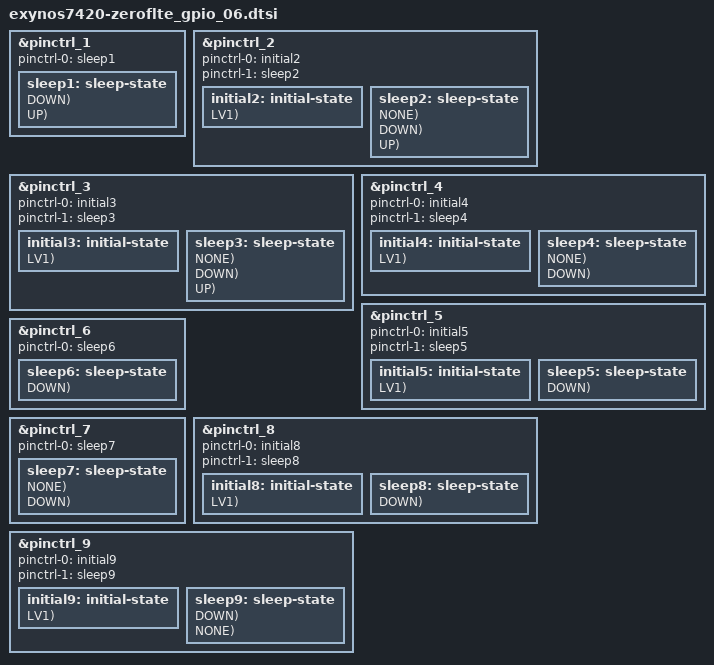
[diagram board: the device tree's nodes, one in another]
/*
 * Copyright (c) 2014 Samsung Electronics Co., Ltd.
 *		http://www.samsung.com
 *
 * This program is free software; you can redistribute it and/or modify
 * it under the terms of the GNU General Public License version 2 as
 * published by the Free Software Foundation.
*/

// Support ZERO-F LTE HW REV06 (b1010)

#include "exynos_gpio_config_macros.dtsi"

// gpz0, gpz1
&pinctrl_1 {
	pinctrl-names = "sleep";
	pinctrl-0 = <&sleep1>;
	sleep1: sleep-state {
		PIN_SLP(gpz0-0, INPUT, DOWN);	/* MM_I2S_CLK */
		PIN_SLP(gpz0-1, INPUT, DOWN);	/* NC */
		PIN_SLP(gpz0-2, INPUT, DOWN);	/* MM_I2S_SYNC */
		PIN_SLP(gpz0-3, INPUT, DOWN);	/* MM_I2S_DO */
		PIN_SLP(gpz0-4, INPUT, DOWN);	/* MM_I2S_DI */
		PIN_SLP(gpz0-5, INPUT, DOWN);	/* NC */
		PIN_SLP(gpz0-6, INPUT, DOWN);	/* NC */

		PIN_SLP(gpz1-0, OUT1, UP);	/* BT_UART_TXD */
		PIN_SLP(gpz1-1, INPUT, UP);	/* BT_UART_RXD */
		PIN_SLP(gpz1-2, INPUT, UP);	/* BT_UART_CTS */
		PIN_SLP(gpz1-3, OUT1, UP);	/* BT_UART_RTS */
	};
};

// gpb0, gpc0 ~ gpc3, gpd0 ~ gpd8, gpg0, gpg3
&pinctrl_2 {
	pinctrl-names = "default","sleep";
	pinctrl-0 = <&initial2>;
	pinctrl-1 = <&sleep2>;
	initial2: initial-state {
		PIN_IN(gpd0-0, DOWN, LV1);	/* NC */
		PIN_IN(gpd0-1, DOWN, LV1);	/* NC */

		PIN_IN(gpd1-4, DOWN, LV1);	/* NC */
		PIN_IN(gpd1-5, DOWN, LV1);	/* NC */

		PIN_IN(gpd2-4, DOWN, LV1);	/* NC */
		PIN_IN(gpd2-6, DOWN, LV1);	/* NC */
		PIN_IN(gpd2-7, DOWN, LV1);	/* NC */

		PIN_IN(gpd4-0, DOWN, LV1);	/* NC */
		PIN_IN(gpd4-1, DOWN, LV1);	/* NC */
		PIN_IN(gpd4-2, DOWN, LV1);	/* NC */
		PIN_IN(gpd4-3, DOWN, LV1);	/* NC */
		PIN_IN(gpd4-4, DOWN, LV1);	/* NC */
	};
	sleep2: sleep-state {
		PIN_SLP(gpb0-0, INPUT, NONE);	/* MEM_SDA */
		PIN_SLP(gpb0-1, INPUT, NONE);	/* MEM_SCL */
		PIN_SLP(gpb0-2, INPUT, DOWN);	/* VTCAM_EEP_SDA */
		PIN_SLP(gpb0-3, INPUT, DOWN);	/* VTCAM_EEP_SCL */
		PIN_SLP(gpb0-4, OUT0, NONE);	/* BUCK6EN */

		PIN_SLP(gpc0-0, INPUT, DOWN);	/* COMP_PAF_INT */
		PIN_SLP(gpc0-1, INPUT, DOWN);	/* TP */
		PIN_SLP(gpc0-2, INPUT, DOWN);	/* CAM_FLASH_EN */
		PIN_SLP(gpc0-3, INPUT, DOWN);	/* CAM_TORCH_EN */
		PIN_SLP(gpc0-4, INPUT, DOWN);	/* VTCAM_RST_N */
		PIN_SLP(gpc0-5, INPUT, DOWN);	/* CAM_RST_N */
		PIN_SLP(gpc0-6, INPUT, DOWN);	/* VTCAM_STBY */
		PIN_SLP(gpc0-7, INPUT, DOWN);	/* COMP_RST_N */

		PIN_SLP(gpc1-0, INPUT, DOWN);	/* CAM_SENSOR_DET */
		PIN_SLP(gpc1-1, INPUT, DOWN);	/* TP */

		PIN_SLP(gpc2-0, INPUT, DOWN);	/* CAM_SDA */
		PIN_SLP(gpc2-1, INPUT, DOWN);	/* CAM_SCL */
		PIN_SLP(gpc2-2, INPUT, DOWN);	/* VTCAM_SDA */
		PIN_SLP(gpc2-3, INPUT, DOWN);	/* VTCAM_SCL */
		PIN_SLP(gpc2-4, INPUT, DOWN);	/* OIS_AF_SDA */
		PIN_SLP(gpc2-5, INPUT, DOWN);	/* OIS_AF_SCL */

		PIN_SLP(gpc3-0, INPUT, DOWN);	/* FROM_SPI_SCLK */
		PIN_SLP(gpc3-1, INPUT, DOWN);	/* FROM_SPI_SSN */
		PIN_SLP(gpc3-2, INPUT, DOWN);	/* FROM_SPI_MISO */
		PIN_SLP(gpc3-3, INPUT, DOWN);	/* FROM_SPI_MOSI */
		PIN_SLP(gpc3-4, INPUT, DOWN);	/* COMP_SPI_SCLK */
		PIN_SLP(gpc3-5, INPUT, DOWN);	/* COMP_SPI_SSN */
		PIN_SLP(gpc3-6, INPUT, DOWN);	/* COMP_SPI_MISO */
		PIN_SLP(gpc3-7, INPUT, DOWN);	/* COMP_SPI_MOSI */

		PIN_SLP(gpd0-0, INPUT, DOWN);	/* NC */
		PIN_SLP(gpd0-1, INPUT, DOWN);	/* NC */
		PIN_SLP(gpd0-2, INPUT, NONE);	/* SUB_PMIC_SDA */
		PIN_SLP(gpd0-3, INPUT, NONE);	/* SUB_PMIC_SCL */

		PIN_SLP(gpd1-0, INPUT, DOWN);	/* AP_RXD */
		PIN_SLP(gpd1-1, INPUT, DOWN);	/* AP_TXD */
		PIN_SLP(gpd1-2, INPUT, DOWN);	/* TOUCH_SDA */
		PIN_SLP(gpd1-3, INPUT, DOWN);	/* TOUCH_SCL */
		PIN_SLP(gpd1-4, INPUT, DOWN);	/* NC */
		PIN_SLP(gpd1-5, INPUT, DOWN);	/* NC */

		PIN_SLP(gpd2-0, INPUT, NONE);	/* SPK_AMP_SDA */
		PIN_SLP(gpd2-1, INPUT, NONE);	/* SPK_AMP_SCL */
		PIN_SLP(gpd2-2, INPUT, NONE);	/* IF_PMIC_SDA */
		PIN_SLP(gpd2-3, INPUT, NONE);	/* IF_PMIC_SCL */
		PIN_SLP(gpd2-4, INPUT, DOWN);	/* NC */
		PIN_SLP(gpd2-5, OUT0, NONE);	/* VIBTONE_PWM */
		PIN_SLP(gpd2-6, INPUT, DOWN);	/* NC */
		PIN_SLP(gpd2-7, INPUT, DOWN);	/* NC */

		PIN_SLP(gpd4-0, INPUT, DOWN);	/* NC */
		PIN_SLP(gpd4-1, INPUT, DOWN);	/* NC  */
		PIN_SLP(gpd4-2, INPUT, DOWN);	/* NC */
		PIN_SLP(gpd4-3, INPUT, DOWN);	/* NC */
		PIN_SLP(gpd4-4, INPUT, DOWN);	/* NC */

		PIN_SLP(gpd5-0, INPUT, DOWN);	/* CP_SPI_CLK */
		PIN_SLP(gpd5-1, INPUT, DOWN);	/* CP_SPI_CSN */
		PIN_SLP(gpd5-2, INPUT, DOWN);	/* CP_SPI_MISO */
		PIN_SLP(gpd5-3, INPUT, DOWN);	/* CP_SPI_MOSI */

		PIN_SLP(gpd6-0, INPUT, DOWN);	/* CODEC_SPI_MOSI */
		PIN_SLP(gpd6-1, INPUT, DOWN);	/* CODEC_SPI_MISO */
		PIN_SLP(gpd6-2, OUT1, UP);	/* SHUB_SPI_SCK */
		PIN_SLP(gpd6-3, OUT1, UP);	/* SHUB_SPI_CSN */
		PIN_SLP(gpd6-4, INPUT, DOWN);	/* SHUB_SPI_MISO */
		PIN_SLP(gpd6-5, OUT1, UP);	/* SHUB_SPI_MOSI */

		PIN_SLP(gpd7-0, INPUT, DOWN);	/* CAM_MCLK */
		PIN_SLP(gpd7-1, INPUT, DOWN);	/* COMP_MCLK */
		PIN_SLP(gpd7-2, INPUT, DOWN);	/* VTCAM_MCLK */

		PIN_SLP(gpd8-0, INPUT, DOWN);	/* CODEC_SPI_SCK */
		PIN_SLP(gpd8-1, INPUT, DOWN);	/* CODEC_SPI_SSN */

		PIN_SLP(gpg0-0, INPUT, DOWN);	/* DISPLAY_TE */
		PIN_SLP(gpg0-1, INPUT, DOWN);	/* DISPLAY_TE */

		PIN_SLP(gpg3-0, INPUT, NONE);	/* AP_PMIC_SDA */
		PIN_SLP(gpg3-1, INPUT, NONE);	/* AP_PMIC_SCL */
		PIN_SLP(gpg3-2, INPUT, NONE);	/* WPC_SDA */
		PIN_SLP(gpg3-3, INPUT, NONE);	/* WPC_SCL */
	};
};

// gpf0 ~ gpf5, gpg1, gpg2, gph1, gpv6
&pinctrl_3 {
	pinctrl-names = "default","sleep";
	pinctrl-0 = <&initial3>;
	pinctrl-1 = <&sleep3>;
	initial3: initial-state {
		PIN_IN(gpf0-0, NONE, LV1);	/* HW_REV(0) */
		PIN_IN(gpf0-1, NONE, LV1);	/* HW_REV(1) */
		PIN_IN(gpf0-2, NONE, LV1);	/* HW_REV(2) */
		PIN_IN(gpf0-3, NONE, LV1);	/* HW_REV(3) */
		PIN_IN(gpf0-5, DOWN, LV1);	/* NC */

		PIN_IN(gpf1-0, DOWN, LV1);	/* NC */
		PIN_IN(gpf1-2, DOWN, LV1);	/* NC */
		PIN_IN(gpf1-3, DOWN, LV1);	/* NC */

		PIN_IN(gpf2-0, DOWN, LV1);	/* NC */
		PIN_IN(gpf2-1, DOWN, LV1);	/* NC */
		PIN_IN(gpf2-2, DOWN, LV1);	/* NC */
		PIN_IN(gpf2-3, DOWN, LV1);	/* NC */

		PIN_IN(gpf3-1, DOWN, LV1);	/* FPS_ID */
		PIN_IN(gpf3-2, DOWN, LV1);	/* NC */

		PIN_IN(gpf5-3, DOWN, LV1);	/* NC */
		PIN_IN(gpf5-5, DOWN, LV1);	/* NC */
		PIN_IN(gpf5-6, DOWN, LV1);	/* WCP_TSB */
		PIN_IN(gpf5-7, DOWN, LV1);	/* NC */

		PIN_IN(gpg1-2, DOWN, LV1);	/* NC */
		PIN_IN(gpg1-3, DOWN, LV1);	/* NC */

		PIN_IN(gph1-0, DOWN, LV1);	/* NC */
		PIN_IN(gph1-1, DOWN, LV1);	/* NC */
		PIN_IN(gph1-2, DOWN, LV1);	/* NC */
		PIN_IN(gph1-3, DOWN, LV1);	/* NC */

		PIN_IN(gpv6-0, DOWN, LV1);	/* NC */
		PIN_IN(gpv6-1, DOWN, LV1);	/* NC */
		PIN_IN(gpv6-2, DOWN, LV1);	/* NC */
	};
	sleep3: sleep-state {
		PIN_SLP(gpf0-0, INPUT, NONE);	/* HW_REV(0) */
		PIN_SLP(gpf0-1, INPUT, NONE);	/* HW_REV(1) */
		PIN_SLP(gpf0-2, INPUT, NONE);	/* HW_REV(2) */
		PIN_SLP(gpf0-3, INPUT, NONE);	/* HW_REV(3) */
		PIN_SLP(gpf0-4, PREV, NONE);	/* AP_CP_STATUS */
		PIN_SLP(gpf0-5, INPUT, DOWN);	/* NC */
		PIN_SLP(gpf0-6, PREV, NONE);	/* PCIE_CLKREQ_L */
		PIN_SLP(gpf0-7, PREV, DOWN);	/* XCCIBYPASS */

		PIN_SLP(gpf1-0, INPUT, DOWN);	/* NC */
		PIN_SLP(gpf1-1, PREV, NONE);	/* CP_RST_N */
		PIN_SLP(gpf1-2, INPUT, DOWN);	/* NC */
		PIN_SLP(gpf1-3, INPUT, DOWN);	/* NC */
		PIN_SLP(gpf1-4, INPUT, DOWN);	/* VTCAM_ID */
		PIN_SLP(gpf1-5, PREV, NONE);	/* NFC_EN */
		PIN_SLP(gpf1-6, PREV, NONE);	/* BTP_LDO_EN1 */
		PIN_SLP(gpf1-7, PREV, NONE);	/* BTP_LDO_EN2 */

		PIN_SLP(gpf2-0, INPUT, DOWN);	/* NC */
		PIN_SLP(gpf2-1, INPUT, DOWN);	/* NC */
		PIN_SLP(gpf2-2, INPUT, DOWN);	/* NC */
		PIN_SLP(gpf2-3, INPUT, DOWN);	/* NC */

		PIN_SLP(gpf3-0, OUT1, NONE);	/* PMIC_WRST_IN */
		PIN_SLP(gpf3-1, INPUT, DOWN);	/* FPS_ID */
		PIN_SLP(gpf3-2, INPUT, DOWN);	/* NC */
		PIN_SLP(gpf3-3, OUT0, NONE);	/* PDA_ACTIVE */
		PIN_SLP(gpf3-4, PREV, NONE);	/* BTP_RST_N */

		PIN_SLP(gpf4-0, PREV, NONE);	/* CODEC_RST_N */
		PIN_SLP(gpf4-1, PREV, NONE);	/* BT_EN */
		PIN_SLP(gpf4-2, PREV, NONE);	/* AP_CP_WAKE */
		PIN_SLP(gpf4-3, OUT0, NONE);	/* DISPLAY_1.6V_EN */
		PIN_SLP(gpf4-4, INPUT, DOWN);	/* SSP_MCU_RESP */
		PIN_SLP(gpf4-5, OUT0, DOWN);	/* SSP_MCU_REQ */
		PIN_SLP(gpf4-6, PREV, NONE);	/* WLAN_EN */
		PIN_SLP(gpf4-7, PREV, NONE);	/* GPS_HUB_EN */

		PIN_SLP(gpf5-0, PREV, NONE);	/* CP_PMIC_PWR_EN */
		PIN_SLP(gpf5-1, PREV, NONE);	/* AP_CP_DUMP_NOTI_n */
		PIN_SLP(gpf5-2, PREV, NONE);	/* FACTORY_DISCHARGING */
		PIN_SLP(gpf5-3, INPUT, DOWN);	/* NC */
		PIN_SLP(gpf5-4, OUT0, DOWN);	/* NFC_FIRM */
		PIN_SLP(gpf5-5, INPUT, DOWN);	/* NC */
		PIN_SLP(gpf5-6, INPUT, DOWN);	/* WCP_TSB */
		PIN_SLP(gpf5-7, INPUT, DOWN);	/* NC */

		PIN_SLP(gpg1-0, INPUT, NONE);	/* SMPL_WARN_AP */
		PIN_SLP(gpg1-1, PREV, NONE);	/* PMIC_BUCK6_DVS */
		PIN_SLP(gpg1-2, INPUT, DOWN);	/* NC */
		PIN_SLP(gpg1-3, INPUT, DOWN);	/* NC */
		PIN_SLP(gpg1-4, INPUT, DOWN);	/* TSP_ID */

		PIN_SLP(gpg2-0, PREV, NONE);	/* PCIE_RST_L */
		PIN_SLP(gpg2-1, INPUT, DOWN);	/* PAD_DBGSRCSEL */
		PIN_SLP(gpg2-2, PREV, UP);	/* PCIE_LINK_RESET */
		PIN_SLP(gpg2-3, PREV, DOWN);	/* XCPUAXI3SELACE */
		PIN_SLP(gpg2-4, PREV, NONE);	/* UFS_REFCLK */

		PIN_SLP(gph1-0, INPUT, DOWN);	/* NC */
		PIN_SLP(gph1-1, INPUT, DOWN);	/* NC */
		PIN_SLP(gph1-2, INPUT, DOWN);	/* NC */
		PIN_SLP(gph1-3, INPUT, DOWN);	/* NC */
		PIN_SLP(gph1-4, OUT0, NONE);	/* XBOOTLDO0 */
		PIN_SLP(gph1-5, PREV, NONE);	/* UFS_RST_N */

		PIN_SLP(gpv6-0, INPUT, DOWN);	/* NC */
		PIN_SLP(gpv6-1, INPUT, DOWN);	/* NC */
		PIN_SLP(gpv6-2, INPUT, DOWN);	/* NC */
	};
};

// gpj0
&pinctrl_4 {
	pinctrl-names = "default","sleep";
	pinctrl-0 = <&initial4>;
	pinctrl-1 = <&sleep4>;
	initial4: initial-state {
		PIN_IN(gpj0-2, DOWN, LV1);	/* NC */
	};
	sleep4: sleep-state {
		PIN_SLP(gpj0-0, INPUT, NONE);	/* HRM_SDA */
		PIN_SLP(gpj0-1, INPUT, NONE);	/* HRM_SCL */
		PIN_SLP(gpj0-2, INPUT, DOWN);	/* NC */
	};
};

// gpj1
&pinctrl_5 {
	pinctrl-names = "default","sleep";
	pinctrl-0 = <&initial5>;
	pinctrl-1 = <&sleep5>;
	initial5: initial-state {
		PIN_IN(gpj1-2, DOWN, LV1);	/* NC */
	};
	sleep5: sleep-state {
		PIN_SLP(gpj1-0, INPUT, DOWN);	/* TSP_SDA */
		PIN_SLP(gpj1-1, INPUT, DOWN);	/* TSP_SCL */
		PIN_SLP(gpj1-2, INPUT, DOWN);	/* NC */
	};
};

// gpg4
&pinctrl_6 {
	pinctrl-names = "sleep";
	pinctrl-0 = <&sleep6>;
	sleep6: sleep-state {
		PIN_SLP(gpg4-0, INPUT, DOWN);	/* ESE_SPI_SCLK */
		PIN_SLP(gpg4-1, INPUT, DOWN);	/* ESE_SPI_SSN */
		PIN_SLP(gpg4-2, INPUT, DOWN);	/* ESE_SPI_MISO */
		PIN_SLP(gpg4-3, INPUT, DOWN);	/* ESE_SPI_MOSI */
	};
};

// gpv7
&pinctrl_7 {
	pinctrl-names = "sleep";
	pinctrl-0= <&sleep7>;
	sleep7: sleep-state {
		PIN_SLP(gpv7-0, OUT0, NONE);	/* BTP_SPI_CLK */
		PIN_SLP(gpv7-1, OUT0, NONE);	/* BTP_SPI_CS_N */
		PIN_SLP(gpv7-2, INPUT, DOWN);	/* BTP_SPI_MISO */
		PIN_SLP(gpv7-3, OUT0, NONE);	/* BTP_SPI_MOSI */
		PIN_SLP(gpv7-4, PREV, NONE);	/* BTP_OCP_EN */
	};
};

// gpr4
&pinctrl_8 {
	pinctrl-names = "default","sleep";
	pinctrl-0 = <&initial8>;
	pinctrl-1 = <&sleep8>;
	initial8: initial-state {
		PIN_IN(gpr4-0, DOWN, LV1);	/* NC */
		PIN_IN(gpr4-1, DOWN, LV1);	/* NC */
		PIN_IN(gpr4-2, DOWN, LV1);	/* NC */
		PIN_IN(gpr4-3, DOWN, LV1);	/* NC */
		PIN_IN(gpr4-4, DOWN, LV1);	/* NC */
		PIN_IN(gpr4-5, DOWN, LV1);	/* NC */
		PIN_IN(gpr4-6, DOWN, LV1);	/* NC */
	};
	sleep8: sleep-state {
		PIN_SLP(gpr4-0, INPUT, DOWN);	/* NC */
		PIN_SLP(gpr4-1, INPUT, DOWN);	/* NC */
		PIN_SLP(gpr4-2, INPUT, DOWN);	/* NC */
		PIN_SLP(gpr4-3, INPUT, DOWN);	/* NC */
		PIN_SLP(gpr4-4, INPUT, DOWN);	/* NC */
		PIN_SLP(gpr4-5, INPUT, DOWN);	/* NC */
		PIN_SLP(gpr4-6, INPUT, DOWN);	/* NC */
	};
};

// gpr0 ~ gpr3
&pinctrl_9 {
	pinctrl-names = "default","sleep";
	pinctrl-0 = <&initial9>;
	pinctrl-1 = <&sleep9>;
	initial9: initial-state {
		PIN_IN(gpr0-0, DOWN, LV1);	/* NC */
		PIN_IN(gpr0-1, DOWN, LV1);	/* NC */
		PIN_IN(gpr0-2, DOWN, LV1);	/* NC */
		PIN_IN(gpr0-3, DOWN, LV1);	/* NC */

		PIN_IN(gpr1-0, DOWN, LV1);	/* NC */
		PIN_IN(gpr1-1, DOWN, LV1);	/* NC */
		PIN_IN(gpr1-2, DOWN, LV1);	/* NC */
		PIN_IN(gpr1-3, DOWN, LV1);	/* NC */
		PIN_IN(gpr1-4, DOWN, LV1);	/* NC */
		PIN_IN(gpr1-5, DOWN, LV1);	/* NC */
		PIN_IN(gpr1-6, DOWN, LV1);	/* NC */
		PIN_IN(gpr1-7, DOWN, LV1);	/* NC */

		PIN_IN(gpr2-3, DOWN, LV1);	/* NC */
		PIN_IN(gpr2-4, DOWN, LV1);	/* NC */

		PIN_IN(gpr3-2, DOWN, LV1);	/* NC */
	};
	sleep9: sleep-state {
		PIN_SLP(gpr0-0, INPUT, DOWN);	/* NC */
		PIN_SLP(gpr0-1, INPUT, DOWN);	/* NC */
		PIN_SLP(gpr0-2, INPUT, DOWN);	/* NC */
		PIN_SLP(gpr0-3, INPUT, DOWN);	/* NC */

		PIN_SLP(gpr1-0, INPUT, DOWN);	/* NC */
		PIN_SLP(gpr1-1, INPUT, DOWN);	/* NC */
		PIN_SLP(gpr1-2, INPUT, DOWN);	/* NC */
		PIN_SLP(gpr1-3, INPUT, DOWN);	/* NC */
		PIN_SLP(gpr1-4, INPUT, DOWN);	/* NC */
		PIN_SLP(gpr1-5, INPUT, DOWN);	/* NC */
		PIN_SLP(gpr1-6, INPUT, DOWN);	/* NC */
		PIN_SLP(gpr1-7, INPUT, DOWN);	/* NC */

		PIN_SLP(gpr2-0, INPUT, NONE);	/* PCIE_CLKREQ_L */
		PIN_SLP(gpr2-1, INPUT, DOWN);	/* OLED_ID */
		PIN_SLP(gpr2-2, INPUT, NONE);	/* SUB_PMIC_IRQ_N */
		PIN_SLP(gpr2-3, INPUT, DOWN);	/* NC */
		PIN_SLP(gpr2-4, INPUT, DOWN);	/* NC */

		PIN_SLP(gpr3-0, INPUT, DOWN);	/* M_DISPLAY_RST */
		PIN_SLP(gpr3-1, INPUT, DOWN);	/* DISPLAY_DET */
		PIN_SLP(gpr3-2, INPUT, DOWN);	/* NC */
		PIN_SLP(gpr3-3, INPUT, NONE);	/* DUAL_SIM */
		PIN_SLP(gpr3-4, PREV, NONE);	/* BT_WAKE */
		PIN_SLP(gpr3-5, INPUT, DOWN);	/* IFC_SENSE_INT_AP */
		PIN_SLP(gpr3-6, PREV, NONE);    /* USB_EAR_DET */
		PIN_SLP(gpr3-7, INPUT, DOWN);	/* FG_ERR */
	};
};

